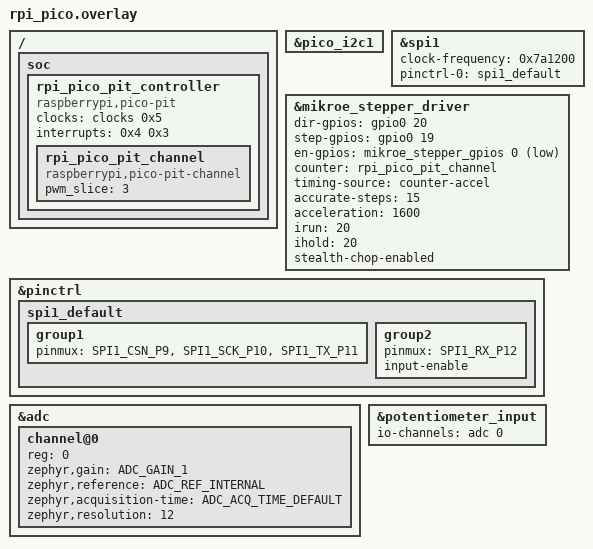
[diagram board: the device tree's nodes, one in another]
/*
 * Copyright (c) 2025 Navimatix GmbH
 * SPDX-License-Identifier: Apache-2.0
 */

microbus_i2c: &pico_i2c1 {};
mikrobus_spi: &spi1 {};
#include "mikroe_silent_step_2.dtsi"
#include "potentiometer_input.dtsi"

#include <zephyr/dt-bindings/gpio/gpio.h>

&mikroe_stepper_driver {
	dir-gpios = <&gpio0 20 0>;				/* GP20 */
	step-gpios = <&gpio0 19 0>;				/* GP19 */
	en-gpios = <&mikroe_stepper_gpios 0 GPIO_ACTIVE_LOW>;

	/* Timing source configuration. */
	counter = <&rpi_pico_pit_channel>;
	timing-source = "counter-accel";
	accurate-steps = <15>;
	acceleration = <1600>;

	irun = <20>;
	ihold = <20>;
	stealth-chop-enabled;
};

&pinctrl {
	spi1_default: spi1_default {
		group1 {
			pinmux = <SPI1_CSN_P9>, <SPI1_SCK_P10>, <SPI1_TX_P11>;
		};
		group2 {
			pinmux = <SPI1_RX_P12>;
			input-enable;
		};
	};

};

&mikrobus_spi {
	clock-frequency = < 0x7a1200 >;
	pinctrl-0 = <&spi1_default>;
	pinctrl-names = "default";
};

/ {
	soc {
		/* Timer used to generate step signals for the stepper motor. */
		rpi_pico_pit_controller: rpi_pico_pit_controller {
			compatible = "raspberrypi,pico-pit";
			status = "okay";

			clocks = <&clocks 0x5>;
			interrupts = <0x4 0x3>;
			interrupt-names = "PWM_IRQ_WRAP";
			#pico-pit-controller-cells = <0>;

			rpi_pico_pit_channel: rpi_pico_pit_channel {
				compatible = "raspberrypi,pico-pit-channel";
				status = "okay";

				pwm_slice = <3>;
				#pico-pit-channel-cells = <0>;
			};
		};
	};
};

&adc {
	#address-cells = <1>;
	#size-cells = <0>;

	/* ADC channel configuration for the potentiometer. */
	channel@0 {
		reg = <0>;
		zephyr,gain = "ADC_GAIN_1";
		zephyr,reference = "ADC_REF_INTERNAL";
		zephyr,acquisition-time = <ADC_ACQ_TIME_DEFAULT>;
		zephyr,resolution = <12>;
	};
};

&potentiometer_input {
	io-channels = <&adc 0>;
};
